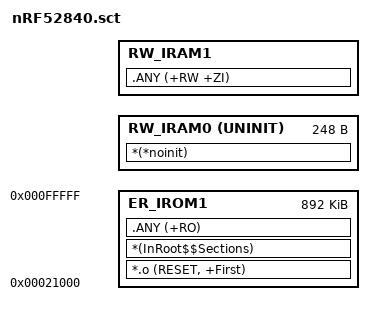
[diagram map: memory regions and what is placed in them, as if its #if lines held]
#! armcc -E

#if !defined(MBED_APP_START)
  #define MBED_APP_START 0x21000
#endif

#if !defined(MBED_APP_SIZE)
  #define MBED_APP_SIZE 0xDF000
#endif

#if defined(MBED_CONF_SD_RAM_ALLOC)
  #define APP_RAM_BASE (0x20000000 + MBED_CONF_SD_RAM_ALLOC)
#else
  #define APP_RAM_BASE 0x20003288
#endif

LR_IROM1 MBED_APP_START MBED_APP_SIZE  {
  ER_IROM1 MBED_APP_START MBED_APP_SIZE  {
   *.o (RESET, +First)
   *(InRoot$$Sections)
   .ANY (+RO)
  }
  RW_IRAM0 APP_RAM_BASE UNINIT 0x000000F8  { ;no init section
        *(*noinit)
  }
  RW_IRAM1 (APP_RAM_BASE + 0xF8) (0x20040000 - APP_RAM_BASE - 0xF8)  {
   .ANY (+RW +ZI)
  }
}
